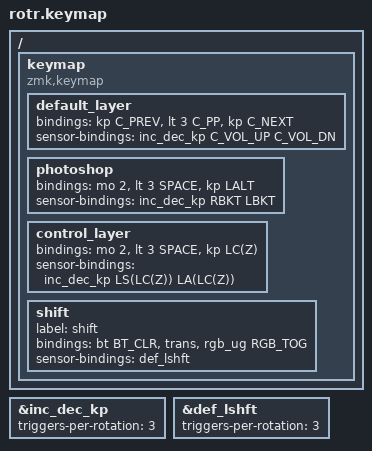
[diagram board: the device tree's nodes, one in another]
#include <behaviors.dtsi>
#include <dt-bindings/zmk/keys.h>
#include <dt-bindings/zmk/rgb.h>
#include <dt-bindings/zmk/bt.h>
#define control_layer 2

&inc_dec_kp {
	triggers-per-rotation = <3>;
};
&def_lshft {
	triggers-per-rotation = <3>;
};

/ {
	keymap {
		compatible = "zmk,keymap";

		default_layer {
			//PREV | PLAY/PAUSE | NEXT
			bindings = <&kp C_PREV &lt 3 C_PP &kp C_NEXT>;
			sensor-bindings = <&inc_dec_kp C_VOL_UP C_VOL_DN>;
		};
		photoshop {
			//CONTROL | SPACE | ALT
			bindings = <&mo 2 &lt 3 SPACE &kp LALT>;
			sensor-bindings = <&inc_dec_kp RBKT LBKT>;
		};
		control_layer {
			//PREV | PLAY/PAUSE | NEXT
			bindings = <&mo 2 &lt 3 SPACE &kp LC(Z)>;
			sensor-bindings = <&inc_dec_kp LS(LC(Z)) LA(LC(Z))>;
			
		};
		shift {
			label = "shift";
			//PREV | PLAY/PAUSE | NEXT
			bindings = <&bt BT_CLR &trans &rgb_ug RGB_TOG>;
			sensor-bindings = <&def_lshft>;
		};
	};
};
